# BL602 register map
Vendor: bouffalolab; Series: WiFi BT
Registers are 32-bit, read-write, reset 0x0 unless marked. A register's access mark holds for its fields unless they carry their own. Offsets are from the block's base; [hi:lo] are bit positions; {n}, {i} and the like mark numbered series.

## CKS — Checksum engine
Base 0x4000A700
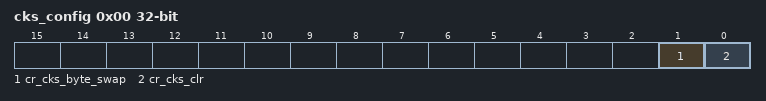
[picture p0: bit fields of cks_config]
0x00 cks_config
  [1] cr_cks_byte_swap — Endianness.
    0=little_endian; 1=big_endian
  [0] cr_cks_clr
0x04 data_in — Checksum data in
  [7:0] data_in wo
0x08 cks_out reset 0xFFFF — Checksum value out
  [15:0] cks_out ro

## DMA — DMA control
Base 0x4000C000
0x00 DMA_IntStatus
  [7:0] IntStatus ro
0x04 DMA_IntTCStatus
  [7:0] IntTCStatus ro
0x08 DMA_IntTCClear
  [7:0] IntTCClear wo
0x0C DMA_IntErrorStatus
  [7:0] IntErrorStatus ro
0x10 DMA_IntErrClr
  [7:0] IntErrClr wo
0x14 DMA_RawIntTCStatus
  [7:0] RawIntTCStatus ro
0x18 DMA_RawIntErrorStatus
  [7:0] RawIntErrorStatus ro
0x1C DMA_EnbldChns
  [7:0] EnabledChannels ro
0x20 DMA_SoftBReq
0x24 DMA_SoftSReq
0x28 DMA_SoftLBReq
0x2C DMA_SoftLSReq
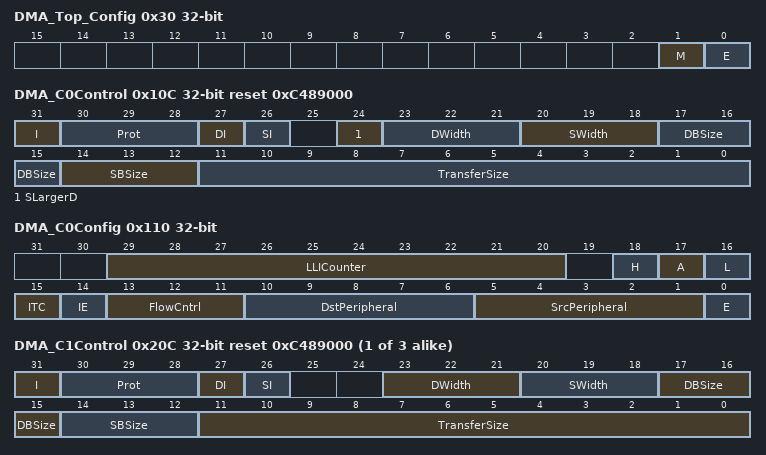
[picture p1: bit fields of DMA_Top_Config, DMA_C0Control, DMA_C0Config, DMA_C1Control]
0x30 DMA_Top_Config
  [1] M, [0] E
0x34 DMA_Sync
{0x100+0x100*i} DMA_C{i}SrcAddr (i=0..3)
  [31:0] SrcAddr
{0x104+0x100*i} DMA_C{i}DstAddr (i=0..3)
  [31:0] DstAddr
0x108 DMA_C0LLI
  [31:0] LLI
0x10C DMA_C0Control reset 0xC489000
  [31] I, [30:28] Prot, [27] DI, [26] SI, [24] SLargerD, [23:21] DWidth, [20:18] SWidth, [17:15] DBSize, [14:12] SBSize, [11:0] TransferSize
0x110 DMA_C0Config
  [29:20] LLICounter ro, [18] H, [17] A ro, [16] L, [15] ITC, [14] IE, [13:11] FlowCntrl, [10:6] DstPeripheral, [5:1] SrcPeripheral, [0] E
{0x108+0x100*i} DMA_C{i}LLI (i=1..3)
  [31:2] LLI
{0x10C+0x100*i} DMA_C{i}Control reset 0xC489000 (i=1..3)
  [31] I, [30:28] Prot, [27] DI, [26] SI, [23:21] DWidth, [20:18] SWidth, [17:15] DBSize, [14:12] SBSize, [11:0] TransferSize
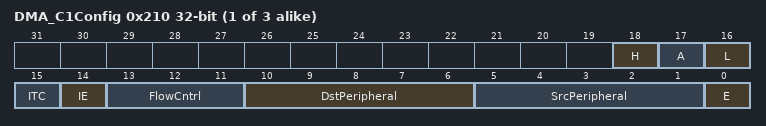
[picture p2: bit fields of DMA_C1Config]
{0x110+0x100*i} DMA_C{i}Config (i=1..3)
  [18] H, [17] A ro, [16] L, [15] ITC, [14] IE, [13:11] FlowCntrl, [10:6] DstPeripheral, [5:1] SrcPeripheral, [0] E

## PDS — Sleep control (power-down sleep)
Base 0x4000E000
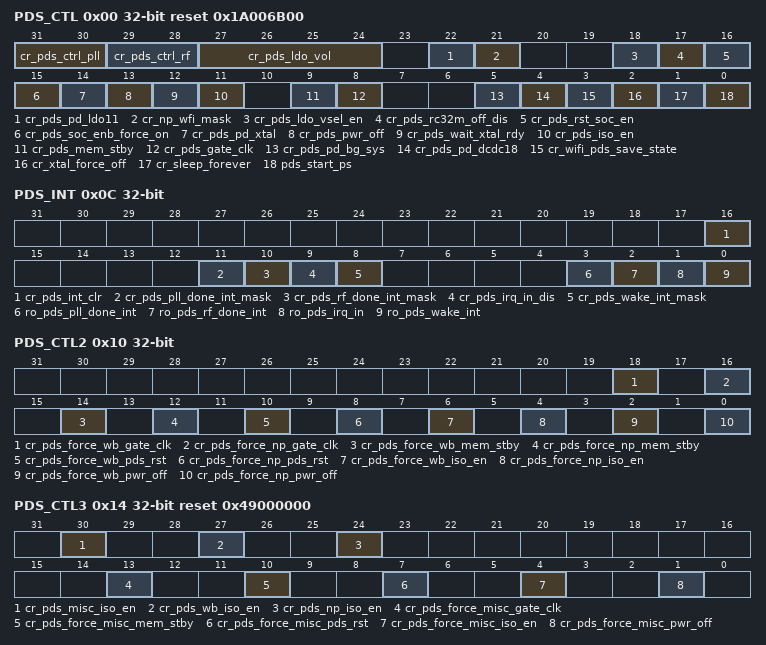
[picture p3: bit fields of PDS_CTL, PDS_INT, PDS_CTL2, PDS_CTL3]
0x00 PDS_CTL reset 0x1A006B00
  [31:30] cr_pds_ctrl_pll, [29:28] cr_pds_ctrl_rf, [27:24] cr_pds_ldo_vol, [22] cr_pds_pd_ldo11, [21] cr_np_wfi_mask, [18] cr_pds_ldo_vsel_en, [17] cr_pds_rc32m_off_dis, [16] cr_pds_rst_soc_en, [15] cr_pds_soc_enb_force_on, [14] cr_pds_pd_xtal, [13] cr_pds_pwr_off, [12] cr_pds_wait_xtal_rdy, [11] cr_pds_iso_en, [9] cr_pds_mem_stby, [8] cr_pds_gate_clk, [5] cr_pds_pd_bg_sys, [4] cr_pds_pd_dcdc18, [3] cr_wifi_pds_save_state, [2] cr_xtal_force_off, [1] cr_sleep_forever, [0] pds_start_ps
0x04 PDS_TIME1 reset 0xCA8
  [31:0] cr_sleep_duration
0x0C PDS_INT
  [16] cr_pds_int_clr, [11] cr_pds_pll_done_int_mask, [10] cr_pds_rf_done_int_mask, [9] cr_pds_irq_in_dis, [8] cr_pds_wake_int_mask, [3] ro_pds_pll_done_int ro, [2] ro_pds_rf_done_int ro, [1] ro_pds_irq_in ro, [0] ro_pds_wake_int ro
0x10 PDS_CTL2
  [18] cr_pds_force_wb_gate_clk, [16] cr_pds_force_np_gate_clk, [14] cr_pds_force_wb_mem_stby, [12] cr_pds_force_np_mem_stby, [10] cr_pds_force_wb_pds_rst, [8] cr_pds_force_np_pds_rst, [6] cr_pds_force_wb_iso_en, [4] cr_pds_force_np_iso_en, [2] cr_pds_force_wb_pwr_off, [0] cr_pds_force_np_pwr_off
0x14 PDS_CTL3 reset 0x49000000
  [30] cr_pds_misc_iso_en, [27] cr_pds_wb_iso_en, [24] cr_pds_np_iso_en, [13] cr_pds_force_misc_gate_clk, [10] cr_pds_force_misc_mem_stby, [7] cr_pds_force_misc_pds_rst, [4] cr_pds_force_misc_iso_en, [1] cr_pds_force_misc_pwr_off
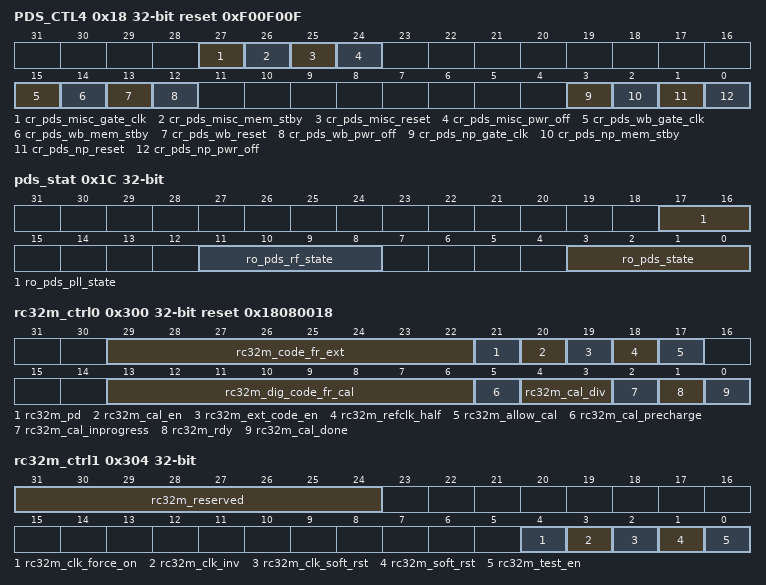
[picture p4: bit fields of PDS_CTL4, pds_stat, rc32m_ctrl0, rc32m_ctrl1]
0x18 PDS_CTL4 reset 0xF00F00F
  [27] cr_pds_misc_gate_clk, [26] cr_pds_misc_mem_stby, [25] cr_pds_misc_reset, [24] cr_pds_misc_pwr_off, [15] cr_pds_wb_gate_clk, [14] cr_pds_wb_mem_stby, [13] cr_pds_wb_reset, [12] cr_pds_wb_pwr_off, [3] cr_pds_np_gate_clk, [2] cr_pds_np_mem_stby, [1] cr_pds_np_reset, [0] cr_pds_np_pwr_off
0x1C pds_stat ro
  [17:16] ro_pds_pll_state, [11:8] ro_pds_rf_state, [3:0] ro_pds_state
0x20 pds_ram1
  [7:0] cr_np_sram_pwr
0x300 rc32m_ctrl0 reset 0x18080018
  [29:22] rc32m_code_fr_ext, [21] rc32m_pd, [20] rc32m_cal_en, [19] rc32m_ext_code_en, [18] rc32m_refclk_half, [17] rc32m_allow_cal, [13:6] rc32m_dig_code_fr_cal ro, [5] rc32m_cal_precharge ro, [4:3] rc32m_cal_div, [2] rc32m_cal_inprogress ro, [1] rc32m_rdy ro, [0] rc32m_cal_done ro
0x304 rc32m_ctrl1
  [31:24] rc32m_reserved, [4] rc32m_clk_force_on, [3] rc32m_clk_inv, [2] rc32m_clk_soft_rst, [1] rc32m_soft_rst, [0] rc32m_test_en
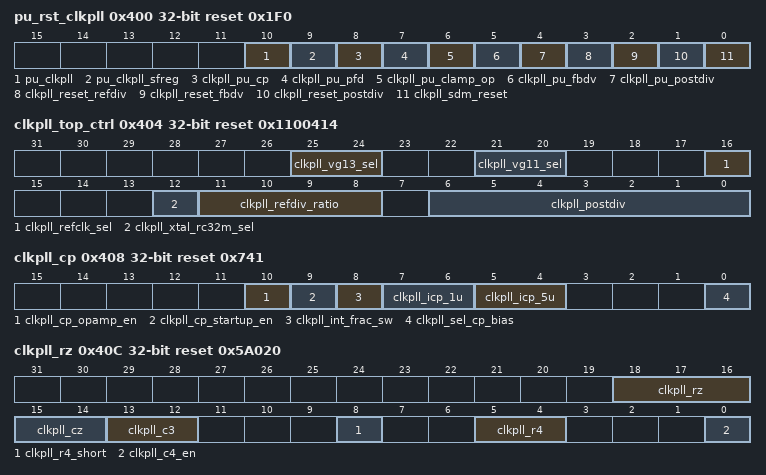
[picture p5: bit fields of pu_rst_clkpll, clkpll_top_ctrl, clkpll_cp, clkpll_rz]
0x400 pu_rst_clkpll reset 0x1F0
  [10] pu_clkpll, [9] pu_clkpll_sfreg, [8] clkpll_pu_cp, [7] clkpll_pu_pfd, [6] clkpll_pu_clamp_op, [5] clkpll_pu_fbdv, [4] clkpll_pu_postdiv, [3] clkpll_reset_refdiv, [2] clkpll_reset_fbdv, [1] clkpll_reset_postdiv, [0] clkpll_sdm_reset
0x404 clkpll_top_ctrl reset 0x1100414
  [25:24] clkpll_vg13_sel, [21:20] clkpll_vg11_sel, [16] clkpll_refclk_sel, [12] clkpll_xtal_rc32m_sel, [11:8] clkpll_refdiv_ratio, [6:0] clkpll_postdiv
0x408 clkpll_cp reset 0x741
  [10] clkpll_cp_opamp_en, [9] clkpll_cp_startup_en, [8] clkpll_int_frac_sw, [7:6] clkpll_icp_1u, [5:4] clkpll_icp_5u, [0] clkpll_sel_cp_bias
0x40C clkpll_rz reset 0x5A020
  [18:16] clkpll_rz, [15:14] clkpll_cz, [13:12] clkpll_c3, [8] clkpll_r4_short, [5:4] clkpll_r4, [0] clkpll_c4_en
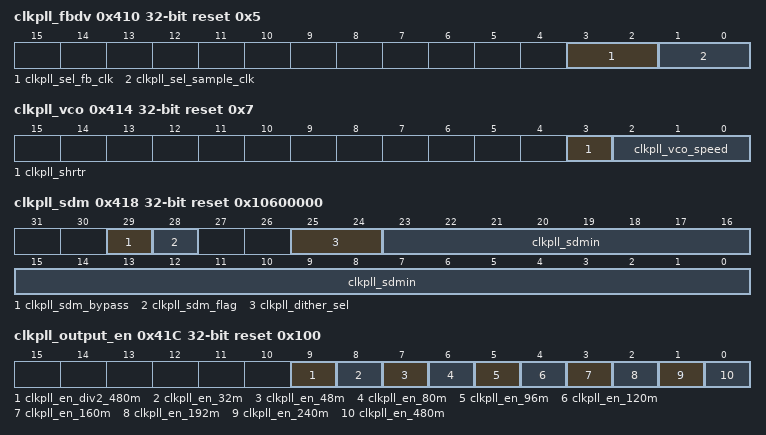
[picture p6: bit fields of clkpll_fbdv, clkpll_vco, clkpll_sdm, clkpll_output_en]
0x410 clkpll_fbdv reset 0x5
  [3:2] clkpll_sel_fb_clk, [1:0] clkpll_sel_sample_clk
0x414 clkpll_vco reset 0x7
  [3] clkpll_shrtr, [2:0] clkpll_vco_speed
0x418 clkpll_sdm reset 0x10600000
  [29] clkpll_sdm_bypass, [28] clkpll_sdm_flag, [25:24] clkpll_dither_sel, [23:0] clkpll_sdmin
0x41C clkpll_output_en reset 0x100
  [9] clkpll_en_div2_480m, [8] clkpll_en_32m, [7] clkpll_en_48m, [6] clkpll_en_80m, [5] clkpll_en_96m, [4] clkpll_en_120m, [3] clkpll_en_160m, [2] clkpll_en_192m, [1] clkpll_en_240m, [0] clkpll_en_480m

## HBN — Deep Sleep Control (Hibernation)
Base 0x4000F000
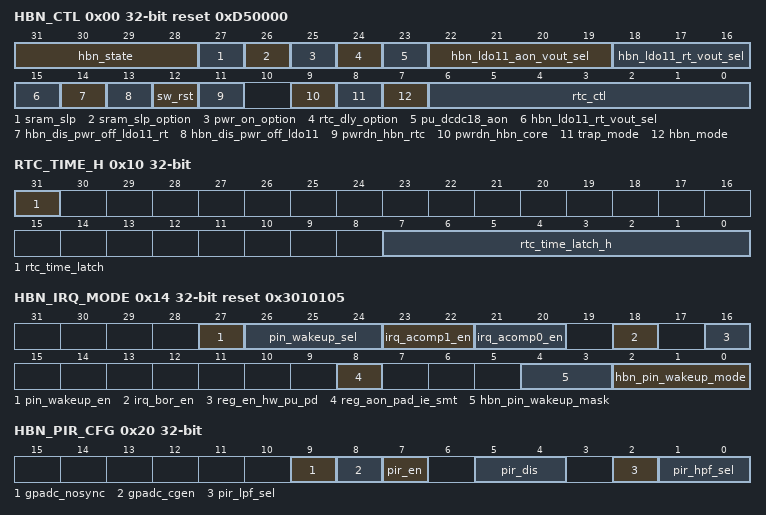
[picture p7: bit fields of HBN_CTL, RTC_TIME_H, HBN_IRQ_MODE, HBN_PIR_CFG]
0x00 HBN_CTL reset 0xD50000
  [31:28] hbn_state ro, [27] sram_slp ro, [26] sram_slp_option, [25] pwr_on_option, [24] rtc_dly_option, [23] pu_dcdc18_aon, [22:19] hbn_ldo11_aon_vout_sel, [18:15] hbn_ldo11_rt_vout_sel, [14] hbn_dis_pwr_off_ldo11_rt, [13] hbn_dis_pwr_off_ldo11, [12] sw_rst, [11] pwrdn_hbn_rtc, [9] pwrdn_hbn_core, [8] trap_mode ro, [7] hbn_mode wo, [6:0] rtc_ctl
0x04 HBN_TIME_L
0x08 HBN_TIME_H
  [7:0] hbn_time_h
0x0C RTC_TIME_L ro
  [31:0] rtc_time_latch_l
0x10 RTC_TIME_H
  [31] rtc_time_latch wo, [7:0] rtc_time_latch_h ro
0x14 HBN_IRQ_MODE reset 0x3010105
  [27] pin_wakeup_en, [26:24] pin_wakeup_sel, [23:22] irq_acomp1_en, [21:20] irq_acomp0_en, [18] irq_bor_en, [16] reg_en_hw_pu_pd, [8] reg_aon_pad_ie_smt, [4:3] hbn_pin_wakeup_mask, [2:0] hbn_pin_wakeup_mode
0x18 HBN_IRQ_STAT ro
  [31:0] irq_stat
0x1C HBN_IRQ_CLR wo
  [31:0] irq_clr
0x20 HBN_PIR_CFG
  [9] gpadc_nosync, [8] gpadc_cgen, [7] pir_en, [5:4] pir_dis, [2] pir_lpf_sel, [1:0] pir_hpf_sel
0x24 HBN_PIR_VTH reset 0x3FF
  [13:0] pir_vth
0x28 HBN_PIR_INTERVAL reset 0xA3D
  [11:0] pir_interval
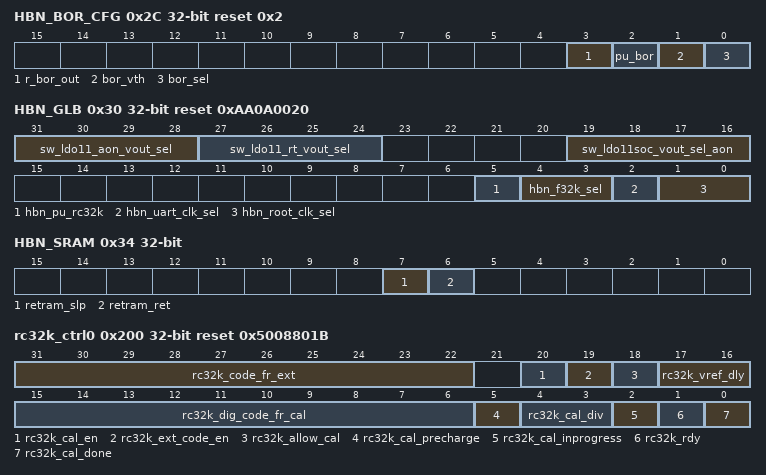
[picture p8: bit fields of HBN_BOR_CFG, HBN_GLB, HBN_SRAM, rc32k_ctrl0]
0x2C HBN_BOR_CFG reset 0x2
  [3] r_bor_out ro, [2] pu_bor, [1] bor_vth, [0] bor_sel
0x30 HBN_GLB reset 0xAA0A0020
  [31:28] sw_ldo11_aon_vout_sel, [27:24] sw_ldo11_rt_vout_sel, [19:16] sw_ldo11soc_vout_sel_aon, [5] hbn_pu_rc32k, [4:3] hbn_f32k_sel, [2] hbn_uart_clk_sel, [1:0] hbn_root_clk_sel
0x34 HBN_SRAM
  [7] retram_slp, [6] retram_ret
0x100 HBN_RSV0
0x104 HBN_RSV1 reset 0xFFFFFFFF
0x108 HBN_RSV2
0x10C HBN_RSV3 reset 0xFFFFFFFF
0x200 rc32k_ctrl0 reset 0x5008801B
  [31:22] rc32k_code_fr_ext, [20] rc32k_cal_en, [19] rc32k_ext_code_en, [18] rc32k_allow_cal, [17:16] rc32k_vref_dly, [15:6] rc32k_dig_code_fr_cal ro, [5] rc32k_cal_precharge ro, [4:3] rc32k_cal_div, [2] rc32k_cal_inprogress ro, [1] rc32k_rdy ro, [0] rc32k_cal_done ro
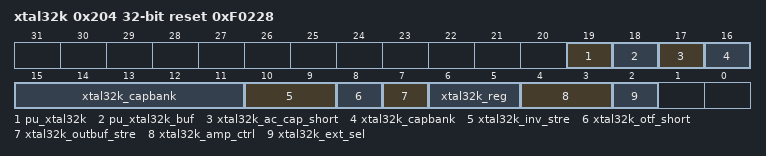
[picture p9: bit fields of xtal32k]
0x204 xtal32k reset 0xF0228
  [19] pu_xtal32k, [18] pu_xtal32k_buf, [17] xtal32k_ac_cap_short, [16:11] xtal32k_capbank, [10:9] xtal32k_inv_stre, [8] xtal32k_otf_short, [7] xtal32k_outbuf_stre, [6:5] xtal32k_reg, [4:3] xtal32k_amp_ctrl, [2] xtal32k_ext_sel
